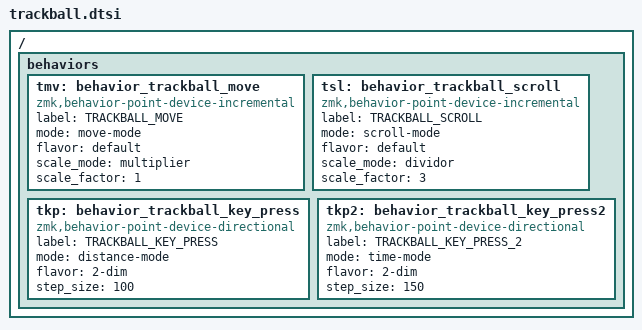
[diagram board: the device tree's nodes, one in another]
/ {
	behaviors {
		/omit-if-no-ref/ tmv: behavior_trackball_move {
			compatible = "zmk,behavior-point-device-incremental";
			label = "TRACKBALL_MOVE";
			#trackball-binding-cells = <0>;
      mode = "move-mode";
      flavor = "default";
      scale_mode = "multiplier";
      scale_factor = <1>;
		};
	};

	behaviors {
		/omit-if-no-ref/ tsl: behavior_trackball_scroll {
			compatible = "zmk,behavior-point-device-incremental";
			label = "TRACKBALL_SCROLL";
			#trackball-binding-cells = <0>;
      mode = "scroll-mode";
      flavor = "default";
      scale_mode = "dividor";
      scale_factor = <3>;
		};
	};

	behaviors {
		/omit-if-no-ref/ tkp: behavior_trackball_key_press {
			compatible = "zmk,behavior-point-device-directional";
			label = "TRACKBALL_KEY_PRESS";
			#trackball-binding-cells = <4>;
      mode = "distance-mode";
      flavor = "2-dim";
      step_size = <100>;
		};
	};

	behaviors {
		/omit-if-no-ref/ tkp2: behavior_trackball_key_press2 {
			compatible = "zmk,behavior-point-device-directional";
			label = "TRACKBALL_KEY_PRESS_2";
			#trackball-binding-cells = <4>;
      mode = "time-mode";
      flavor = "2-dim";
      step_size = <150>;
		};
	};
};
